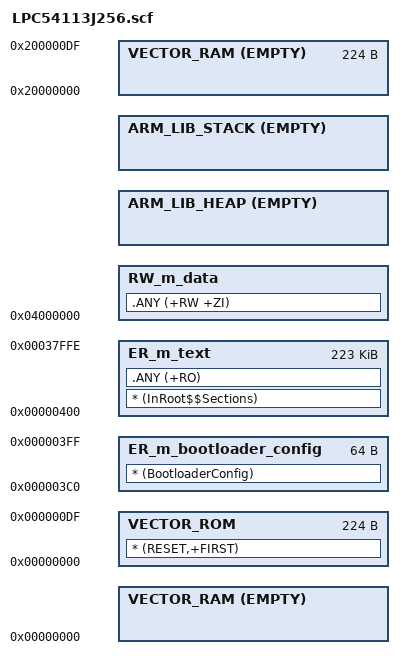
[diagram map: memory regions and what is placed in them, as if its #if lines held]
#! armcc -E
/*
** ###################################################################
**     Processors:          LPC54113J256BD64
**                          LPC54113J256UK49
**
**     Compiler:            Keil ARM C/C++ Compiler
**     Reference manual:    LPC5411x User manual Rev. 1.0 16 February 2016
**     Version:             rev. 1.0, 2016-04-29
**     Build:               b160606
**
**     Abstract:
**         Linker file for the Keil ARM C/C++ Compiler
**
**     Copyright (c) 2016 Freescale Semiconductor, Inc.
**     All rights reserved.
**
**     Redistribution and use in source and binary forms, with or without modification,
**     are permitted provided that the following conditions are met:
**
**     o Redistributions of source code must retain the above copyright notice, this list
**       of conditions and the following disclaimer.
**
**     o Redistributions in binary form must reproduce the above copyright notice, this
**       list of conditions and the following disclaimer in the documentation and/or
**       other materials provided with the distribution.
**
**     o Neither the name of Freescale Semiconductor, Inc. nor the names of its
**       contributors may be used to endorse or promote products derived from this
**       software without specific prior written permission.
**
**     THIS SOFTWARE IS PROVIDED BY THE COPYRIGHT HOLDERS AND CONTRIBUTORS "AS IS" AND
**     ANY EXPRESS OR IMPLIED WARRANTIES, INCLUDING, BUT NOT LIMITED TO, THE IMPLIED
**     WARRANTIES OF MERCHANTABILITY AND FITNESS FOR A PARTICULAR PURPOSE ARE
**     DISCLAIMED. IN NO EVENT SHALL THE COPYRIGHT HOLDER OR CONTRIBUTORS BE LIABLE FOR
**     ANY DIRECT, INDIRECT, INCIDENTAL, SPECIAL, EXEMPLARY, OR CONSEQUENTIAL DAMAGES
**     (INCLUDING, BUT NOT LIMITED TO, PROCUREMENT OF SUBSTITUTE GOODS OR SERVICES;
**     LOSS OF USE, DATA, OR PROFITS; OR BUSINESS INTERRUPTION) HOWEVER CAUSED AND ON
**     ANY THEORY OF LIABILITY, WHETHER IN CONTRACT, STRICT LIABILITY, OR TORT
**     (INCLUDING NEGLIGENCE OR OTHERWISE) ARISING IN ANY WAY OUT OF THE USE OF THIS
**     SOFTWARE, EVEN IF ADVISED OF THE POSSIBILITY OF SUCH DAMAGE.
**
**     http:                 www.freescale.com
**     mail:                 support@freescale.com
**
** ###################################################################
*/

#if (defined(__ram_vector_table__))
  #define __ram_vector_table_size__    0x000000E0
#else
  #define __ram_vector_table_size__    0x00000000
#endif

#define m_interrupts_start             0x00000000
#define m_interrupts_size              0x000000E0

#define m_bootloader_config_start      0x000003C0
#define m_bootloader_config_size       0x00000040

#define m_text_start                   0x00000400
#define m_text_size                    0x00037BFF

#define m_interrupts_ram_start         0x20000000
#define m_interrupts_ram_size          __ram_vector_table_size__

#define m_data_start                   (m_interrupts_ram_start + m_interrupts_ram_size)
#define m_data_size                    (0x00010000 - m_interrupts_ram_size)

#define m_data_2_start                 0x20010000
#define m_data_2_size                  0x00010000

#define m_data_3_start                 0x20020000
#define m_data_3_size                  0x00008000

#define m_sramx_start                  0x04000000
#define m_sramx_size                   0x00008000

/* Sizes */
#if (defined(__stack_size__))
  #define Stack_Size                   __stack_size__
#else
  #define Stack_Size                   0x0800
#endif

#if (defined(__heap_size__))
  #define Heap_Size                    __heap_size__
#else
  #define Heap_Size                    0x0000
#endif

LR_m_text m_text_start m_text_size { ; load region size_region
  ER_m_text m_text_start m_text_size  {  ; load address = execution address
    * (InRoot$$Sections)
    .ANY (+RO)
  }
  
  RW_m_data m_sramx_start m_sramx_size-Stack_Size-Heap_Size { ; RW data
    .ANY (+RW +ZI)
  }
  
  ARM_LIB_HEAP (ImageLimit(RW_m_data)) EMPTY Heap_Size { ; Heap region growing up
  }
  ARM_LIB_STACK (ImageLimit(ARM_LIB_HEAP) + Stack_Size) EMPTY -Stack_Size { ; Stack region growing down
  }
}

LR_m_interrupts m_interrupts_start m_interrupts_size {
#if (!defined(__ram_vector_table__))
  VECTOR_RAM m_interrupts_start EMPTY 0 {
  }
#endif
  VECTOR_ROM m_interrupts_start m_interrupts_size { ; load address = execution address
    * (RESET,+FIRST)
  }
}

LR_m_bootloader_config m_bootloader_config_start m_bootloader_config_size {
  ER_m_bootloader_config m_bootloader_config_start m_bootloader_config_size { ; load address = execution address
    * (BootloaderConfig)
  }
}

#if (defined(__ram_vector_table__))
LR_m_interrupts_ram m_interrupts_ram_start m_interrupts_ram_size {
  VECTOR_RAM m_interrupts_ram_start EMPTY m_interrupts_ram_size {
  }
}
#endif
